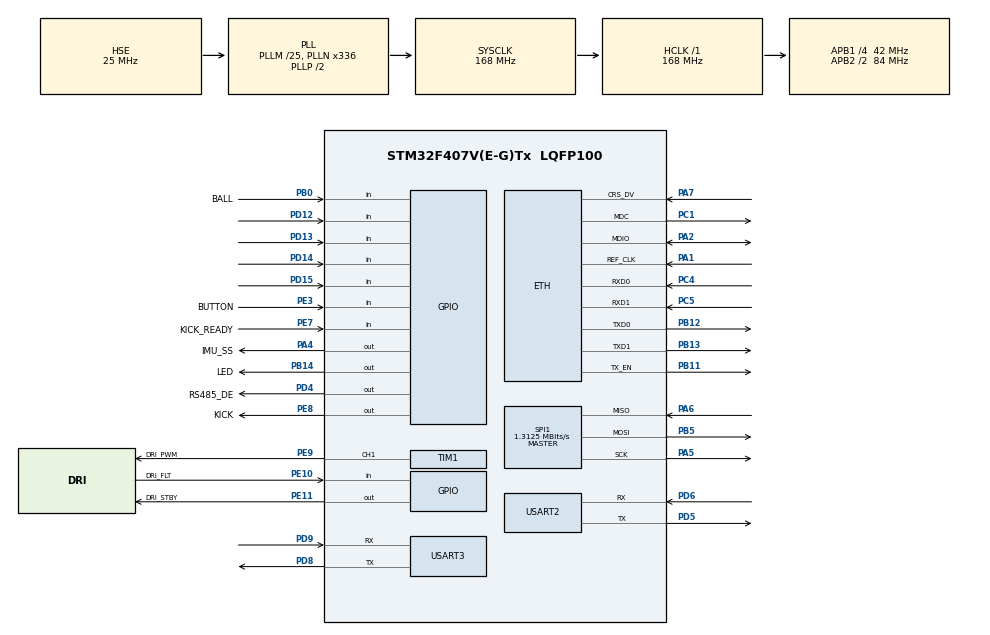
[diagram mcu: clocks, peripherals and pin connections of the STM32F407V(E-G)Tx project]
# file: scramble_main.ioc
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Dma.Request0=SPI1_RX
Dma.Request1=SPI1_TX
Dma.Request2=USART3_RX
Dma.Request3=USART3_TX
Dma.Request4=USART2_RX
Dma.Request5=USART2_TX
Dma.SPI1_RX.0.Direction=DMA_PERIPH_TO_MEMORY
Dma.SPI1_RX.0.FIFOMode=DMA_FIFOMODE_DISABLE
Dma.SPI1_RX.0.Instance=DMA2_Stream0
Dma.SPI1_RX.0.MemDataAlignment=DMA_MDATAALIGN_BYTE
Dma.SPI1_RX.0.MemInc=DMA_MINC_ENABLE
Dma.SPI1_RX.0.Mode=DMA_NORMAL
Dma.SPI1_RX.0.PeriphDataAlignment=DMA_PDATAALIGN_BYTE
Dma.SPI1_RX.0.PeriphInc=DMA_PINC_DISABLE
Dma.SPI1_RX.0.Priority=DMA_PRIORITY_LOW
Dma.SPI1_TX.1.Direction=DMA_MEMORY_TO_PERIPH
Dma.SPI1_TX.1.FIFOMode=DMA_FIFOMODE_DISABLE
Dma.SPI1_TX.1.Instance=DMA2_Stream3
Dma.SPI1_TX.1.MemDataAlignment=DMA_MDATAALIGN_BYTE
Dma.SPI1_TX.1.MemInc=DMA_MINC_ENABLE
Dma.SPI1_TX.1.Mode=DMA_NORMAL
Dma.SPI1_TX.1.PeriphDataAlignment=DMA_PDATAALIGN_BYTE
Dma.SPI1_TX.1.PeriphInc=DMA_PINC_DISABLE
Dma.SPI1_TX.1.Priority=DMA_PRIORITY_LOW
Dma.USART2_RX.4.Direction=DMA_PERIPH_TO_MEMORY
Dma.USART2_RX.4.FIFOMode=DMA_FIFOMODE_DISABLE
Dma.USART2_RX.4.Instance=DMA1_Stream5
Dma.USART2_RX.4.MemDataAlignment=DMA_MDATAALIGN_BYTE
Dma.USART2_RX.4.MemInc=DMA_MINC_ENABLE
Dma.USART2_RX.4.Mode=DMA_CIRCULAR
Dma.USART2_RX.4.PeriphDataAlignment=DMA_PDATAALIGN_BYTE
Dma.USART2_RX.4.PeriphInc=DMA_PINC_DISABLE
Dma.USART2_RX.4.Priority=DMA_PRIORITY_LOW
Dma.USART2_TX.5.Direction=DMA_MEMORY_TO_PERIPH
Dma.USART2_TX.5.FIFOMode=DMA_FIFOMODE_DISABLE
Dma.USART2_TX.5.Instance=DMA1_Stream6
Dma.USART2_TX.5.MemDataAlignment=DMA_MDATAALIGN_BYTE
Dma.USART2_TX.5.MemInc=DMA_MINC_ENABLE
Dma.USART2_TX.5.Mode=DMA_NORMAL
Dma.USART2_TX.5.PeriphDataAlignment=DMA_PDATAALIGN_BYTE
Dma.USART2_TX.5.PeriphInc=DMA_PINC_DISABLE
Dma.USART2_TX.5.Priority=DMA_PRIORITY_LOW
Dma.USART3_RX.2.Direction=DMA_PERIPH_TO_MEMORY
Dma.USART3_RX.2.FIFOMode=DMA_FIFOMODE_DISABLE
Dma.USART3_RX.2.Instance=DMA1_Stream1
Dma.USART3_RX.2.MemDataAlignment=DMA_MDATAALIGN_BYTE
Dma.USART3_RX.2.MemInc=DMA_MINC_ENABLE
Dma.USART3_RX.2.Mode=DMA_CIRCULAR
Dma.USART3_RX.2.PeriphDataAlignment=DMA_PDATAALIGN_BYTE
Dma.USART3_RX.2.PeriphInc=DMA_PINC_DISABLE
Dma.USART3_RX.2.Priority=DMA_PRIORITY_HIGH
Dma.USART3_TX.3.Direction=DMA_MEMORY_TO_PERIPH
Dma.USART3_TX.3.FIFOMode=DMA_FIFOMODE_DISABLE
Dma.USART3_TX.3.Instance=DMA1_Stream3
Dma.USART3_TX.3.MemDataAlignment=DMA_MDATAALIGN_BYTE
Dma.USART3_TX.3.MemInc=DMA_MINC_ENABLE
Dma.USART3_TX.3.Mode=DMA_NORMAL
Dma.USART3_TX.3.PeriphDataAlignment=DMA_PDATAALIGN_BYTE
Dma.USART3_TX.3.PeriphInc=DMA_PINC_DISABLE
Dma.USART3_TX.3.Priority=DMA_PRIORITY_HIGH
ETH.MediaInterface=ETH_MEDIA_INTERFACE_RMII
FREERTOS.HEAP_NUMBER=2
FREERTOS.MEMORY_ALLOCATION=0
FREERTOS.Tasks01=defaultTask,0,512,StartDefaultTask,Default,NULL,Dynamic,NULL,NULL
FREERTOS.configTOTAL_HEAP_SIZE=30720
LWIP.GATEWAY_ADDRESS=192.168.011.001
LWIP.IP_ADDRESS=192.168.011.060
LWIP.LWIP_DHCP=0
LWIP.LWIP_TCP=0
LWIP.NETMASK_ADDRESS=255.255.255.000
LWIP.Version=v2.0.3_Cube
Mcu.Family=STM32F4
Mcu.Name=STM32F407V(E-G)Tx
Mcu.Package=LQFP100
NVIC.DMA1_Stream1_IRQn=true\:5\:0\:false\:false\:true\:true\:false
NVIC.DMA1_Stream3_IRQn=true\:5\:0\:false\:false\:true\:true\:false
NVIC.DMA1_Stream5_IRQn=true\:5\:0\:false\:false\:true\:true\:false
NVIC.DMA1_Stream6_IRQn=true\:5\:0\:false\:false\:true\:true\:false
NVIC.DMA2_Stream0_IRQn=true\:5\:0\:false\:false\:true\:true\:false
NVIC.DMA2_Stream3_IRQn=true\:5\:0\:false\:false\:true\:true\:false
NVIC.ETH_IRQn=true\:5\:0\:true\:false\:true\:true\:false
NVIC.PriorityGroup=NVIC_PRIORITYGROUP_4
NVIC.TIM1_UP_TIM10_IRQn=true\:0\:0\:false\:false\:true\:false\:false
NVIC.TimeBase=TIM1_UP_TIM10_IRQn
NVIC.TimeBaseIP=TIM10
NVIC.USART2_IRQn=true\:0\:0\:false\:false\:true\:false\:true
NVIC.USART3_IRQn=true\:0\:0\:true\:false\:true\:false\:true
PA1.Mode=RMII
PA1.Signal=ETH_REF_CLK
PA13.GPIO_Label=SWDIO
PA13.Mode=Serial_Wire
PA13.Signal=SYS_JTMS-SWDIO
PA14.GPIO_Label=SWCLK
PA14.Mode=Serial_Wire
PA14.Signal=SYS_JTCK-SWCLK
PA2.Mode=RMII
PA2.Signal=ETH_MDIO
PA4.GPIO_Label=IMU_SS
PA4.PinState=GPIO_PIN_SET
PA4.Signal=GPIO_Output
PA5.Mode=Full_Duplex_Master
PA5.Signal=SPI1_SCK
PA6.Mode=Full_Duplex_Master
PA6.Signal=SPI1_MISO
PA7.Mode=RMII
PA7.Signal=ETH_CRS_DV
PB0.GPIO_Label=BALL
PB0.GPIO_PuPd=GPIO_NOPULL
PB0.Signal=GPIO_Input
PB11.Mode=RMII
PB11.Signal=ETH_TX_EN
PB12.Mode=RMII
PB12.Signal=ETH_TXD0
PB13.Mode=RMII
PB13.Signal=ETH_TXD1
PB14.GPIO_Label=LED
PB14.GPIO_Speed=GPIO_SPEED_FREQ_HIGH
PB14.Signal=GPIO_Output
PB5.Mode=Full_Duplex_Master
PB5.Signal=SPI1_MOSI
PC1.Mode=RMII
PC1.Signal=ETH_MDC
PC4.Mode=RMII
PC4.Signal=ETH_RXD0
PC5.Mode=RMII
PC5.Signal=ETH_RXD1
PD12.GPIO_PuPd=GPIO_PULLDOWN
PD12.Signal=GPIO_Input
PD13.GPIO_PuPd=GPIO_PULLDOWN
PD13.Signal=GPIO_Input
PD14.GPIO_PuPd=GPIO_PULLDOWN
PD14.Signal=GPIO_Input
PD15.GPIO_PuPd=GPIO_PULLDOWN
PD15.Signal=GPIO_Input
PD4.GPIO_Label=RS485_DE
PD4.GPIO_Speed=GPIO_SPEED_FREQ_HIGH
PD4.Signal=GPIO_Output
PD5.Mode=Asynchronous
PD5.Signal=USART2_TX
PD6.Mode=Asynchronous
PD6.Signal=USART2_RX
PD8.Mode=Asynchronous
PD8.Signal=USART3_TX
PD9.Mode=Asynchronous
PD9.Signal=USART3_RX
PE10.GPIO_Label=DRI_FLT
PE10.Signal=GPIO_Input
PE11.GPIO_Label=DRI_STBY
PE11.GPIO_ModeDefaultOutputPP=GPIO_MODE_OUTPUT_PP
PE11.GPIO_PuPd=GPIO_NOPULL
PE11.GPIO_Speed=GPIO_SPEED_FREQ_HIGH
PE11.PinState=GPIO_PIN_RESET
PE11.Signal=GPIO_Output
PE3.GPIO_Label=BUTTON
PE3.GPIO_PuPd=GPIO_PULLUP
PE3.Signal=GPIO_Input
PE7.GPIO_Label=KICK_READY
PE7.GPIO_PuPd=GPIO_PULLDOWN
PE7.Signal=GPIO_Input
PE8.GPIO_Label=KICK
PE8.GPIO_Speed=GPIO_SPEED_FREQ_HIGH
PE8.Signal=GPIO_Output
PE9.GPIO_Label=DRI_PWM
PE9.Signal=S_TIM1_CH1
PH0-OSC_IN.GPIO_Label=PH0-OSC_IN
PH0-OSC_IN.Mode=HSE-External-Oscillator
PH0-OSC_IN.Signal=RCC_OSC_IN
PH1-OSC_OUT.GPIO_Label=PH1-OSC_OUT
PH1-OSC_OUT.Mode=HSE-External-Oscillator
PH1-OSC_OUT.Signal=RCC_OSC_OUT
ProjectManager.HeapSize=0x200
ProjectManager.StackSize=0x400
ProjectManager.TargetToolchain=TrueSTUDIO
RCC.48MHZClocksFreq_Value=48000000
RCC.AHBFreq_Value=168000000
RCC.APB1CLKDivider=RCC_HCLK_DIV4
RCC.APB1Freq_Value=42000000
RCC.APB1TimFreq_Value=84000000
RCC.APB2CLKDivider=RCC_HCLK_DIV2
RCC.APB2Freq_Value=84000000
RCC.APB2TimFreq_Value=168000000
RCC.CortexFreq_Value=168000000
RCC.HCLKFreq_Value=168000000
RCC.HSE_VALUE=25000000
RCC.HSI_VALUE=16000000
RCC.LSE_VALUE=32768
RCC.PLLM=25
RCC.PLLN=336
RCC.PLLQ=7
RCC.PLLSourceVirtual=RCC_PLLSOURCE_HSE
RCC.SYSCLKFreq_VALUE=168000000
RCC.SYSCLKSource=RCC_SYSCLKSOURCE_PLLCLK
RCC.VCOOutputFreq_Value=336000000
SH.S_TIM1_CH1.0=TIM1_CH1,PWM Generation1 CH1
SPI1.BaudRatePrescaler=SPI_BAUDRATEPRESCALER_64
SPI1.CLKPhase=SPI_PHASE_2EDGE
SPI1.CLKPolarity=SPI_POLARITY_HIGH
SPI1.CRCCalculation=SPI_CRCCALCULATION_ENABLE
SPI1.CalculateBaudRate=1.3125 MBits/s
SPI1.Direction=SPI_DIRECTION_2LINES
SPI1.Mode=SPI_MODE_MASTER
SPI1.VirtualType=VM_MASTER
TIM1.Channel-PWM\ Generation1\ CH1=TIM_CHANNEL_1
TIM1.OCPolarity_1=TIM_OCPOLARITY_LOW
TIM1.Period=1000
TIM1.Prescaler=0
USART2.VirtualMode=VM_ASYNC
USART3.VirtualMode=VM_ASYNC
VP_FREERTOS_VS_ENABLE.Mode=Enabled
VP_LWIP_VS_Enabled.Mode=Enabled
VP_SYS_VS_tim10.Mode=TIM10
board=scramble_main

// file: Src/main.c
/**
  ******************************************************************************
  * @file           : main.c
  * @brief          : Main program body
  ******************************************************************************
  * This notice applies to any and all portions of this file
  * that are not between comment pairs USER CODE BEGIN and
  * USER CODE END. Other portions of this file, whether
  * inserted by the user or by software development tools
  * are owned by their respective copyright owners.
  *
  * Copyright (c) 2018 STMicroelectronics International N.V.
  * All rights reserved.
  *
  * Redistribution and use in source and binary forms, with or without
  * modification, are permitted, provided that the following conditions are met:
  *
  * 1. Redistribution of source code must retain the above copyright notice,
  *    this list of conditions and the following disclaimer.
  * 2. Redistributions in binary form must reproduce the above copyright notice,
  *    this list of conditions and the following disclaimer in the documentation
  *    and/or other materials provided with the distribution.
  * 3. Neither the name of STMicroelectronics nor the names of other
  *    contributors to this software may be used to endorse or promote products
  *    derived from this software without specific written permission.
  * 4. This software, including modifications and/or derivative works of this
  *    software, must execute solely and exclusively on microcontroller or
  *    microprocessor devices manufactured by or for STMicroelectronics.
  * 5. Redistribution and use of this software other than as permitted under
  *    this license is void and will automatically terminate your rights under
  *    this license.
  *
  * THIS SOFTWARE IS PROVIDED BY STMICROELECTRONICS AND CONTRIBUTORS "AS IS"
  * AND ANY EXPRESS, IMPLIED OR STATUTORY WARRANTIES, INCLUDING, BUT NOT
  * LIMITED TO, THE IMPLIED WARRANTIES OF MERCHANTABILITY, FITNESS FOR A
  * PARTICULAR PURPOSE AND NON-INFRINGEMENT OF THIRD PARTY INTELLECTUAL PROPERTY
  * RIGHTS ARE DISCLAIMED TO THE FULLEST EXTENT PERMITTED BY LAW. IN NO EVENT
  * SHALL STMICROELECTRONICS OR CONTRIBUTORS BE LIABLE FOR ANY DIRECT, INDIRECT,
  * INCIDENTAL, SPECIAL, EXEMPLARY, OR CONSEQUENTIAL DAMAGES (INCLUDING, BUT NOT
  * LIMITED TO, PROCUREMENT OF SUBSTITUTE GOODS OR SERVICES; LOSS OF USE, DATA,
  * OR PROFITS; OR BUSINESS INTERRUPTION) HOWEVER CAUSED AND ON ANY THEORY OF
  * LIABILITY, WHETHER IN CONTRACT, STRICT LIABILITY, OR TORT (INCLUDING
  * NEGLIGENCE OR OTHERWISE) ARISING IN ANY WAY OUT OF THE USE OF THIS SOFTWARE,
  * EVEN IF ADVISED OF THE POSSIBILITY OF SUCH DAMAGE.
  *
  ******************************************************************************
  */
#include "main.h"
#include "stm32f4xx_hal.h"
#include "cmsis_os.h"
#include "lwip.h"

/* USER CODE BEGIN Includes */
#include "scramble.h"
/* USER CODE END Includes */

SPI_HandleTypeDef hspi1;
DMA_HandleTypeDef hdma_spi1_rx;
DMA_HandleTypeDef hdma_spi1_tx;

TIM_HandleTypeDef htim1;

UART_HandleTypeDef huart2;
UART_HandleTypeDef huart3;
DMA_HandleTypeDef hdma_usart2_rx;
DMA_HandleTypeDef hdma_usart2_tx;
DMA_HandleTypeDef hdma_usart3_rx;
DMA_HandleTypeDef hdma_usart3_tx;

osThreadId defaultTaskHandle;

/* USER CODE BEGIN PV */
/* Private variables ---------------------------------------------------------*/

/* USER CODE END PV */

void SystemClock_Config(void);
static void MX_GPIO_Init(void);
static void MX_DMA_Init(void);
static void MX_USART3_UART_Init(void);
static void MX_USART2_UART_Init(void);
static void MX_SPI1_Init(void);
static void MX_TIM1_Init(void);
void StartDefaultTask(void const * argument);

void HAL_TIM_MspPostInit(TIM_HandleTypeDef *htim);

/* USER CODE BEGIN PFP */
/* Private function prototypes -----------------------------------------------*/

/* USER CODE END PFP */

int main(void)
{

  /* MCU Configuration----------------------------------------------------------*/

  /* Reset of all peripherals, Initializes the Flash interface and the Systick. */
  HAL_Init();

  /* Configure the system clock */
  SystemClock_Config();

  /* Initialize all configured peripherals */
  MX_GPIO_Init();
  MX_DMA_Init();
  MX_USART3_UART_Init();
  MX_USART2_UART_Init();
  MX_SPI1_Init();
  MX_TIM1_Init();
  /* USER CODE BEGIN 2 */

  if (HAL_TIM_PWM_Start(&htim1, TIM_CHANNEL_1) != HAL_OK){
	  Error_Handler();
  }
  /* USER CODE END 2 */

  /* Create the thread(s) */
  /* definition and creation of defaultTask */
  osThreadDef(defaultTask, StartDefaultTask, osPriorityNormal, 0, 512);
  defaultTaskHandle = osThreadCreate(osThread(defaultTask), NULL);

  /* Start scheduler */
  osKernelStart();

  /* We should never get here as control is now taken by the scheduler */

  /* Infinite loop */
	while (1)
	{

	}

}

void SystemClock_Config(void)
{

  RCC_OscInitTypeDef RCC_OscInitStruct;
  RCC_ClkInitTypeDef RCC_ClkInitStruct;

    /**Configure the main internal regulator output voltage
    */
  __HAL_RCC_PWR_CLK_ENABLE();

  __HAL_PWR_VOLTAGESCALING_CONFIG(PWR_REGULATOR_VOLTAGE_SCALE1);

    /**Initializes the CPU, AHB and APB busses clocks
    */
  RCC_OscInitStruct.OscillatorType = RCC_OSCILLATORTYPE_HSE;
  RCC_OscInitStruct.HSEState = RCC_HSE_ON;
  RCC_OscInitStruct.PLL.PLLState = RCC_PLL_ON;
  RCC_OscInitStruct.PLL.PLLSource = RCC_PLLSOURCE_HSE;
  RCC_OscInitStruct.PLL.PLLM = 25;
  RCC_OscInitStruct.PLL.PLLN = 336;
  RCC_OscInitStruct.PLL.PLLP = RCC_PLLP_DIV2;
  RCC_OscInitStruct.PLL.PLLQ = 7;
  if (HAL_RCC_OscConfig(&RCC_OscInitStruct) != HAL_OK)
  {
    _Error_Handler(__FILE__, __LINE__);
  }

    /**Initializes the CPU, AHB and APB busses clocks
    */
  RCC_ClkInitStruct.ClockType = RCC_CLOCKTYPE_HCLK|RCC_CLOCKTYPE_SYSCLK
                              |RCC_CLOCKTYPE_PCLK1|RCC_CLOCKTYPE_PCLK2;
  RCC_ClkInitStruct.SYSCLKSource = RCC_SYSCLKSOURCE_PLLCLK;
  RCC_ClkInitStruct.AHBCLKDivider = RCC_SYSCLK_DIV1;
  RCC_ClkInitStruct.APB1CLKDivider = RCC_HCLK_DIV4;
  RCC_ClkInitStruct.APB2CLKDivider = RCC_HCLK_DIV2;

  if (HAL_RCC_ClockConfig(&RCC_ClkInitStruct, FLASH_LATENCY_5) != HAL_OK)
  {
    _Error_Handler(__FILE__, __LINE__);
  }

    /**Configure the Systick interrupt time
    */
  HAL_SYSTICK_Config(HAL_RCC_GetHCLKFreq()/1000);

    /**Configure the Systick
    */
  HAL_SYSTICK_CLKSourceConfig(SYSTICK_CLKSOURCE_HCLK);

  /* SysTick_IRQn interrupt configuration */
  HAL_NVIC_SetPriority(SysTick_IRQn, 15, 0);
}

/* SPI1 init function */
static void MX_SPI1_Init(void)
{

  /* SPI1 parameter configuration*/
  hspi1.Instance = SPI1;
  hspi1.Init.Mode = SPI_MODE_MASTER;
  hspi1.Init.Direction = SPI_DIRECTION_2LINES;
  hspi1.Init.DataSize = SPI_DATASIZE_8BIT;
  hspi1.Init.CLKPolarity = SPI_POLARITY_HIGH;
  hspi1.Init.CLKPhase = SPI_PHASE_2EDGE;
  hspi1.Init.NSS = SPI_NSS_SOFT;
  hspi1.Init.BaudRatePrescaler = SPI_BAUDRATEPRESCALER_64;
  hspi1.Init.FirstBit = SPI_FIRSTBIT_MSB;
  hspi1.Init.TIMode = SPI_TIMODE_DISABLE;
  hspi1.Init.CRCCalculation = SPI_CRCCALCULATION_ENABLE;
  hspi1.Init.CRCPolynomial = 10;
  if (HAL_SPI_Init(&hspi1) != HAL_OK)
  {
    _Error_Handler(__FILE__, __LINE__);
  }

}

/* TIM1 init function */
static void MX_TIM1_Init(void)
{

  TIM_MasterConfigTypeDef sMasterConfig;
  TIM_OC_InitTypeDef sConfigOC;
  TIM_BreakDeadTimeConfigTypeDef sBreakDeadTimeConfig;

  htim1.Instance = TIM1;
  htim1.Init.Prescaler = 0;
  htim1.Init.CounterMode = TIM_COUNTERMODE_UP;
  htim1.Init.Period = 1000;
  htim1.Init.ClockDivision = TIM_CLOCKDIVISION_DIV1;
  htim1.Init.RepetitionCounter = 0;
  if (HAL_TIM_PWM_Init(&htim1) != HAL_OK)
  {
    _Error_Handler(__FILE__, __LINE__);
  }

  sMasterConfig.MasterOutputTrigger = TIM_TRGO_RESET;
  sMasterConfig.MasterSlaveMode = TIM_MASTERSLAVEMODE_DISABLE;
  if (HAL_TIMEx_MasterConfigSynchronization(&htim1, &sMasterConfig) != HAL_OK)
  {
    _Error_Handler(__FILE__, __LINE__);
  }

  sConfigOC.OCMode = TIM_OCMODE_PWM1;
  sConfigOC.Pulse = 0;
  sConfigOC.OCPolarity = TIM_OCPOLARITY_LOW;
  sConfigOC.OCNPolarity = TIM_OCNPOLARITY_HIGH;
  sConfigOC.OCFastMode = TIM_OCFAST_DISABLE;
  sConfigOC.OCIdleState = TIM_OCIDLESTATE_RESET;
  sConfigOC.OCNIdleState = TIM_OCNIDLESTATE_RESET;
  if (HAL_TIM_PWM_ConfigChannel(&htim1, &sConfigOC, TIM_CHANNEL_1) != HAL_OK)
  {
    _Error_Handler(__FILE__, __LINE__);
  }

  sBreakDeadTimeConfig.OffStateRunMode = TIM_OSSR_DISABLE;
  sBreakDeadTimeConfig.OffStateIDLEMode = TIM_OSSI_DISABLE;
  sBreakDeadTimeConfig.LockLevel = TIM_LOCKLEVEL_OFF;
  sBreakDeadTimeConfig.DeadTime = 0;
  sBreakDeadTimeConfig.BreakState = TIM_BREAK_DISABLE;
  sBreakDeadTimeConfig.BreakPolarity = TIM_BREAKPOLARITY_HIGH;
  sBreakDeadTimeConfig.AutomaticOutput = TIM_AUTOMATICOUTPUT_DISABLE;
  if (HAL_TIMEx_ConfigBreakDeadTime(&htim1, &sBreakDeadTimeConfig) != HAL_OK)
  {
    _Error_Handler(__FILE__, __LINE__);
  }

  HAL_TIM_MspPostInit(&htim1);

}

/* USART2 init function */
static void MX_USART2_UART_Init(void)
{

  huart2.Instance = USART2;
  huart2.Init.BaudRate = 115200;
  huart2.Init.WordLength = UART_WORDLENGTH_8B;
  huart2.Init.StopBits = UART_STOPBITS_1;
  huart2.Init.Parity = UART_PARITY_NONE;
  huart2.Init.Mode = UART_MODE_TX_RX;
  huart2.Init.HwFlowCtl = UART_HWCONTROL_NONE;
  huart2.Init.OverSampling = UART_OVERSAMPLING_16;
  if (HAL_UART_Init(&huart2) != HAL_OK)
  {
    _Error_Handler(__FILE__, __LINE__);
  }

}

/* USART3 init function */
static void MX_USART3_UART_Init(void)
{

  huart3.Instance = USART3;
  huart3.Init.BaudRate = 115200;
  huart3.Init.WordLength = UART_WORDLENGTH_8B;
  huart3.Init.StopBits = UART_STOPBITS_1;
  huart3.Init.Parity = UART_PARITY_NONE;
  huart3.Init.Mode = UART_MODE_TX_RX;
  huart3.Init.HwFlowCtl = UART_HWCONTROL_NONE;
  huart3.Init.OverSampling = UART_OVERSAMPLING_16;
  if (HAL_UART_Init(&huart3) != HAL_OK)
  {
    _Error_Handler(__FILE__, __LINE__);
  }

}

static void MX_DMA_Init(void)
{
  /* DMA controller clock enable */
  __HAL_RCC_DMA2_CLK_ENABLE();
  __HAL_RCC_DMA1_CLK_ENABLE();

  /* DMA interrupt init */
  /* DMA1_Stream1_IRQn interrupt configuration */
  HAL_NVIC_SetPriority(DMA1_Stream1_IRQn, 5, 0);
  HAL_NVIC_EnableIRQ(DMA1_Stream1_IRQn);
  /* DMA1_Stream3_IRQn interrupt configuration */
  HAL_NVIC_SetPriority(DMA1_Stream3_IRQn, 5, 0);
  HAL_NVIC_EnableIRQ(DMA1_Stream3_IRQn);
  /* DMA1_Stream5_IRQn interrupt configuration */
  HAL_NVIC_SetPriority(DMA1_Stream5_IRQn, 5, 0);
  HAL_NVIC_EnableIRQ(DMA1_Stream5_IRQn);
  /* DMA1_Stream6_IRQn interrupt configuration */
  HAL_NVIC_SetPriority(DMA1_Stream6_IRQn, 5, 0);
  HAL_NVIC_EnableIRQ(DMA1_Stream6_IRQn);
  /* DMA2_Stream0_IRQn interrupt configuration */
  HAL_NVIC_SetPriority(DMA2_Stream0_IRQn, 5, 0);
  HAL_NVIC_EnableIRQ(DMA2_Stream0_IRQn);
  /* DMA2_Stream3_IRQn interrupt configuration */
  HAL_NVIC_SetPriority(DMA2_Stream3_IRQn, 5, 0);
  HAL_NVIC_EnableIRQ(DMA2_Stream3_IRQn);

}

/** Configure pins as
        * Analog
        * Input
        * Output
        * EVENT_OUT
        * EXTI
*/
static void MX_GPIO_Init(void)
{

  GPIO_InitTypeDef GPIO_InitStruct;

  /* GPIO Ports Clock Enable */
  __HAL_RCC_GPIOE_CLK_ENABLE();
  __HAL_RCC_GPIOH_CLK_ENABLE();
  __HAL_RCC_GPIOC_CLK_ENABLE();
  __HAL_RCC_GPIOA_CLK_ENABLE();
  __HAL_RCC_GPIOB_CLK_ENABLE();
  __HAL_RCC_GPIOD_CLK_ENABLE();

  /*Configure GPIO pin Output Level */
  HAL_GPIO_WritePin(IMU_SS_GPIO_Port, IMU_SS_Pin, GPIO_PIN_SET);

  /*Configure GPIO pin Output Level */
  HAL_GPIO_WritePin(GPIOE, KICK_Pin|DRI_STBY_Pin, GPIO_PIN_RESET);

  /*Configure GPIO pin Output Level */
  HAL_GPIO_WritePin(LED_GPIO_Port, LED_Pin, GPIO_PIN_RESET);

  /*Configure GPIO pin Output Level */
  HAL_GPIO_WritePin(RS485_DE_GPIO_Port, RS485_DE_Pin, GPIO_PIN_RESET);

  /*Configure GPIO pin : BUTTON_Pin */
  GPIO_InitStruct.Pin = BUTTON_Pin;
  GPIO_InitStruct.Mode = GPIO_MODE_INPUT;
  GPIO_InitStruct.Pull = GPIO_PULLUP;
  HAL_GPIO_Init(BUTTON_GPIO_Port, &GPIO_InitStruct);

  /*Configure GPIO pin : IMU_SS_Pin */
  GPIO_InitStruct.Pin = IMU_SS_Pin;
  GPIO_InitStruct.Mode = GPIO_MODE_OUTPUT_PP;
  GPIO_InitStruct.Pull = GPIO_NOPULL;
  GPIO_InitStruct.Speed = GPIO_SPEED_FREQ_LOW;
  HAL_GPIO_Init(IMU_SS_GPIO_Port, &GPIO_InitStruct);

  /*Configure GPIO pin : BALL_Pin */
  GPIO_InitStruct.Pin = BALL_Pin;
  GPIO_InitStruct.Mode = GPIO_MODE_INPUT;
  GPIO_InitStruct.Pull = GPIO_NOPULL;
  HAL_GPIO_Init(BALL_GPIO_Port, &GPIO_InitStruct);

  /*Configure GPIO pin : KICK_READY_Pin */
  GPIO_InitStruct.Pin = KICK_READY_Pin;
  GPIO_InitStruct.Mode = GPIO_MODE_INPUT;
  GPIO_InitStruct.Pull = GPIO_PULLDOWN;
  HAL_GPIO_Init(KICK_READY_GPIO_Port, &GPIO_InitStruct);

  /*Configure GPIO pins : KICK_Pin DRI_STBY_Pin */
  GPIO_InitStruct.Pin = KICK_Pin|DRI_STBY_Pin;
  GPIO_InitStruct.Mode = GPIO_MODE_OUTPUT_PP;
  GPIO_InitStruct.Pull = GPIO_NOPULL;
  GPIO_InitStruct.Speed = GPIO_SPEED_FREQ_HIGH;
  HAL_GPIO_Init(GPIOE, &GPIO_InitStruct);

  /*Configure GPIO pin : DRI_FLT_Pin */
  GPIO_InitStruct.Pin = DRI_FLT_Pin;
  GPIO_InitStruct.Mode = GPIO_MODE_INPUT;
  GPIO_InitStruct.Pull = GPIO_NOPULL;
  HAL_GPIO_Init(DRI_FLT_GPIO_Port, &GPIO_InitStruct);

  /*Configure GPIO pin : LED_Pin */
  GPIO_InitStruct.Pin = LED_Pin;
  GPIO_InitStruct.Mode = GPIO_MODE_OUTPUT_PP;
  GPIO_InitStruct.Pull = GPIO_NOPULL;
  GPIO_InitStruct.Speed = GPIO_SPEED_FREQ_HIGH;
  HAL_GPIO_Init(LED_GPIO_Port, &GPIO_InitStruct);

  /*Configure GPIO pins : PD12 PD13 PD14 PD15 */
  GPIO_InitStruct.Pin = GPIO_PIN_12|GPIO_PIN_13|GPIO_PIN_14|GPIO_PIN_15;
  GPIO_InitStruct.Mode = GPIO_MODE_INPUT;
  GPIO_InitStruct.Pull = GPIO_PULLDOWN;
  HAL_GPIO_Init(GPIOD, &GPIO_InitStruct);

  /*Configure GPIO pin : RS485_DE_Pin */
  GPIO_InitStruct.Pin = RS485_DE_Pin;
  GPIO_InitStruct.Mode = GPIO_MODE_OUTPUT_PP;
  GPIO_InitStruct.Pull = GPIO_NOPULL;
  GPIO_InitStruct.Speed = GPIO_SPEED_FREQ_HIGH;
  HAL_GPIO_Init(RS485_DE_GPIO_Port, &GPIO_InitStruct);

}

/* StartDefaultTask function */
void StartDefaultTask(void const * argument)
{

  /* USER CODE BEGIN 5 */
	scramble_init();
	scramble_main();
	for(;;);
  /* USER CODE END 5 */
}

void HAL_TIM_PeriodElapsedCallback(TIM_HandleTypeDef *htim)
{
  if (htim->Instance == TIM10) {
    HAL_IncTick();
  }
}

void _Error_Handler(char *file, int line)
{
	while(1)
	{
	}
}

/************************ (C) COPYRIGHT STMicroelectronics *****END OF FILE****/
